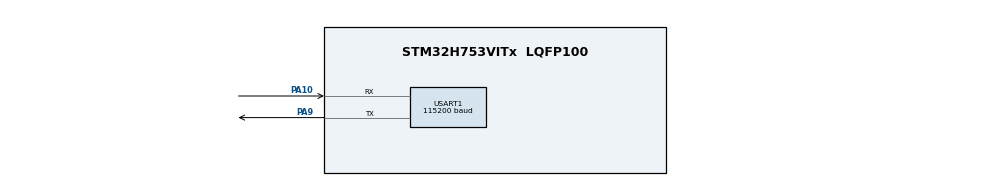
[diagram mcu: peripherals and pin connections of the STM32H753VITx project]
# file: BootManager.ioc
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CORTEX_M7.default_mode_Activation=1
CRC.InputDataFormat=CRC_INPUTDATA_FORMAT_WORDS
Mcu.Family=STM32H7
Mcu.Name=STM32H753VITx
Mcu.Package=LQFP100
NVIC.PriorityGroup=NVIC_PRIORITYGROUP_4
NVIC.USART1_IRQn=true\:0\:0\:false\:false\:true\:true\:true\:true
PA10.Mode=Asynchronous
PA10.Signal=USART1_RX
PA9.Mode=Asynchronous
PA9.Signal=USART1_TX
ProjectManager.HeapSize=0x200
ProjectManager.StackSize=0x400
ProjectManager.TargetToolchain=STM32CubeIDE
RCC.ADCFreq_Value=129000000
RCC.APB1Freq_Value=80000000
RCC.APB2Freq_Value=40000000
RCC.APB3Freq_Value=80000000
RCC.APB4Freq_Value=80000000
RCC.CortexFreq_Value=80000000
RCC.D2PPRE2=RCC_APB2_DIV2
RCC.DIVM1=4
RCC.DIVN1=10
RCC.HCLKFreq_Value=80000000
RCC.PLLFRACN=0
RCC.SYSCLKFreq_VALUE=80000000
RCC.SYSCLKSource=RCC_SYSCLKSOURCE_PLLCLK
RCC.USBFreq_Value=80000000
USART1.BaudRate=115200
USART1.Parity=PARITY_EVEN
USART1.VirtualMode-Asynchronous=VM_ASYNC
USART1.WordLength=WORDLENGTH_9B
VP_CRC_VS_CRC.Mode=CRC_Activate
VP_MEMORYMAP_VS_MEMORYMAP.Mode=CurAppReg
VP_RTC_VS_RTC_Activate.Mode=RTC_Enabled
board=custom

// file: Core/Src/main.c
/* USER CODE BEGIN Header */
/**
  ******************************************************************************
  * @file           : main.c
  * @author 		: Anthony Santos
  * @version 	  	: 1.0.0
  * @brief          : Boot manager entry point and application validation logic
  ******************************************************************************
  * @attention
  *
  * Copyright (c) 2025 STMicroelectronics.
  * All rights reserved.
  *
  * This software is licensed under terms that can be found in the LICENSE file
  * in the root directory of this software component.
  * If no LICENSE file comes with this software, it is provided AS-IS.
  *
  ******************************************************************************
  */
/* USER CODE END Header */
#include "main.h"

/* USER CODE BEGIN Includes */
#include <stdio.h>
#include <stdbool.h>
#include <string.h>
/* USER CODE END Includes */

/* USER CODE BEGIN PTD */
typedef  void (*pFunction)(void);
/* USER CODE END PTD */

/* USER CODE BEGIN PD */
#define BOOTLOADER_FLAG_ADDR ((uint32_t*)0x2001FFF0)
#define BOOTLOADER_FLAG_VALUE 0xDEADBEEF
#define BOOTLOADER_ADDRESS 0x1FF09800
#define APP_ADDRESS  0x08020000
#define APP_CRC_ADDRESS 0x08040000
#define APP_CRC_LENGTH (APP_CRC_ADDRESS - APP_ADDRESS)
/* USER CODE END PD */

CRC_HandleTypeDef hcrc;

RTC_HandleTypeDef hrtc;

UART_HandleTypeDef huart1;

/* USER CODE BEGIN PV */
uint32_t *bootloader_flag;
pFunction JumpToBootloader;
pFunction JumpToApp;
uint32_t JumpAddressBoot;
uint32_t JumpAddressApp;
extern uint32_t _app_image_end;
/* USER CODE END PV */

void SystemClock_Config(void);
static void MPU_Config(void);
static void MX_GPIO_Init(void);
static void MX_RTC_Init(void);
static void MX_USART1_UART_Init(void);
static void MX_CRC_Init(void);

/* USER CODE BEGIN 0 */

/* USER CODE BEGIN 0 */

/**
 * @brief  A manual boot window upon this bootmanagers startup that waits for command 2B.
 * 		   Upon the command being triggered we will jump to bootloader.
 * 		   If no command is sent over UART, code continues as normal.
 */
static void WaitForManualBootWindow(void)
{
    // Flush any stale RX data so we only react to *new* traffic
    __HAL_UART_FLUSH_DRREGISTER(&huart1);
    __HAL_UART_CLEAR_OREFLAG(&huart1);
    __HAL_UART_CLEAR_NEFLAG(&huart1);
    __HAL_UART_CLEAR_FEFLAG(&huart1);
    __HAL_UART_CLEAR_PEFLAG(&huart1);

    const char *msg = "BootMgr: 1s window open — send 0x2B to enter ST bootloader...\r\n";
    HAL_UART_Transmit(&huart1, (uint8_t*)msg, strlen(msg), HAL_MAX_DELAY);

    uint32_t start = HAL_GetTick();
    uint8_t byte = 0;

    while ((HAL_GetTick() - start) < 1000UL)   // ~1 second window
    {
        // Short, non-blocking-ish read (10 ms slices)
        if (HAL_UART_Receive(&huart1, &byte, 1, 10) == HAL_OK)
        {
            if (byte == 0x2B) // '+' == 0x2B
            {
                const char *trig = "BootMgr: Manual bootloader request detected. Jumping...\r\n";
                HAL_UART_Transmit(&huart1, (uint8_t*)trig, strlen(trig), HAL_MAX_DELAY);

                // Optional: clear any RAM flag so we don't loop back here later by accident
                // *BOOTLOADER_FLAG_ADDR = 0;

                JumpToSystemBootloader();
                // no return
            }
            // If you expect larger protocol frames later, you could keep consuming here;
            // for now, any non-0x2B byte is ignored and the window continues.
        }
        // else: timeout -> keep looping until 1s total has elapsed
    }
}
/* USER CODE END 0 */

/**
 * @brief  Jump to the STM32 System Bootloader (e.g. during corrupt state or UART-based flashing).
 *         Cleans up peripherals and disables interrupts before jumping to the
 *         system memory bootloader address.
 */
void JumpToSystemBootloader(void)
{
	uint32_t i=0;
	void (*SysMemBootJump)(void);

	__disable_irq();
	HAL_UART_DeInit(&huart1);
	HAL_RCC_DeInit();
	HAL_RTC_DeInit(&hrtc);
	HAL_CRC_DeInit(&hcrc);
	HAL_DeInit();
	__HAL_RCC_CRC_CLK_DISABLE();

	// Disable Systick
	SysTick->CTRL = 0;
	SysTick->LOAD = 0;
	SysTick->VAL = 0;

	// Reset clock config
	HAL_RCC_DeInit();

	// Clear NVIC interrupt enable and pending registers
	for (i=0;i<5;i++)
	{
		NVIC->ICER[i]=0xFFFFFFFF;
		NVIC->ICPR[i]=0xFFFFFFFF;
	}

	// Re-enable all interrupts
	__enable_irq();

	SysMemBootJump = (void (*)(void)) (*((uint32_t *) ((BOOTLOADER_ADDRESS + 4))));
	__set_MSP(*(uint32_t *) BOOTLOADER_ADDRESS);
	SysMemBootJump();
}

/**
 * @brief  Jump to user application code located at APP_ADDRESS.
 *         Verifies and sets the application's stack pointer and PC.
 */
void JumpToApplication(void)
{
	__disable_irq();

	// Optional but good practice
	HAL_UART_DeInit(&huart1);
	HAL_RCC_DeInit();
	HAL_RTC_DeInit(&hrtc);
	HAL_CRC_DeInit(&hcrc);
	HAL_DeInit();
	__HAL_RCC_CRC_CLK_DISABLE();

	// Kill SysTick
	SysTick->CTRL = 0;
	SysTick->LOAD = 0;
	SysTick->VAL  = 0;

	// Disable all NVIC IRQs
	for (int i = 0; i < 5; i++) {
		NVIC->ICER[i] = 0xFFFFFFFF;
		NVIC->ICPR[i] = 0xFFFFFFFF;
	}

	SCB->VTOR = APP_ADDRESS;

	// Set MSP and jump
	uint32_t app_stack = *(volatile uint32_t*)APP_ADDRESS;
	uint32_t app_reset = *(volatile uint32_t*)(APP_ADDRESS + 4);
	__set_MSP(app_stack);
	void (*app_entry)(void) = (void*)app_reset;

	app_entry();
	while(1);
}

/**
 * @brief  Validates application code by checking its initial stack pointer and reset vector.
 * @retval true if both SP and PC are in valid memory ranges and the PC has the Thumb bit set.
 */
bool IsApplicationValid(void)
{
    uint32_t appStack = *(__IO uint32_t*)APP_ADDRESS;
    uint32_t appResetHandler = *(__IO uint32_t*)(APP_ADDRESS + 4);

    // Reject if either value is erased / corrupt
   if (appStack == 0xFFFFFFFF || appResetHandler == 0xFFFFFFFF)
	   return false;

    bool stack_valid =
        ((appStack >= 0x24000000U && appStack <= 0x2407FFFFU) ||
         (appStack >= 0x20000000U && appStack <= 0x2001FFFFU) ||
         (appStack >= 0x30000000U && appStack <= 0x30047FFFU) ||
         (appStack >= 0x38000000U && appStack <= 0x3800FFFFU));
    bool reset_valid = (appResetHandler >= APP_ADDRESS &&
                        appResetHandler <= 0x080FFFFF &&
                        (appResetHandler & 0x1)); // Thumb bit set
    char msg[100];
        snprintf(msg, sizeof(msg), "Validating App:\r\n  SP Valid: %s\r\n  PC Valid: %s\r\n",
                 stack_valid ? "YES" : "NO",
                 reset_valid ? "YES" : "NO");
        HAL_UART_Transmit(&huart1, (uint8_t*)msg, strlen(msg), HAL_MAX_DELAY);
    return stack_valid && reset_valid;
}

/**
 * @brief  Validates the application using CRC32.
 *         Computes CRC over app region and compares it with stored value at APP_CRC_ADDRESS.
 * @retval true if CRC matches
 */
bool IsApplicationValidCRC(void)
{
    __HAL_RCC_CRC_CLK_ENABLE();
    HAL_CRC_DeInit(&hcrc);
    HAL_CRC_Init(&hcrc);
    __HAL_CRC_DR_RESET(&hcrc);

    uint8_t* app_bytes = (uint8_t*)APP_ADDRESS;
    uint32_t length_bytes = (APP_CRC_ADDRESS - APP_ADDRESS);

    uint32_t crc_value = 0xFFFFFFFF;
    for (uint32_t i = 0; i < length_bytes; ++i)
    {
        uint32_t i_data = app_bytes[i];
        crc_value = HAL_CRC_Accumulate(&hcrc, &i_data, 1);
    }

    uint32_t stored_crc = *(uint32_t*)APP_CRC_ADDRESS;

    char msg[128];
    snprintf(msg, sizeof(msg),
             "Validating App CRC (bytewise):\r\n  Calculated: 0x%08lX\r\n  Stored:     0x%08lX\r\n  Match:      %s\r\n",
             crc_value, stored_crc, (crc_value == stored_crc) ? "YES" : "NO");
    HAL_UART_Transmit(&huart1, (uint8_t*)msg, strlen(msg), HAL_MAX_DELAY);

    return crc_value == stored_crc;
}

/* USER CODE END 0 */

int main(void)
{

  /* MPU Configuration--------------------------------------------------------*/
  MPU_Config();

  /* MCU Configuration--------------------------------------------------------*/

  /* Reset of all peripherals, Initializes the Flash interface and the Systick. */
  HAL_Init();

  /* Configure the system clock */
  SystemClock_Config();

  /* Initialize all configured peripherals */
  MX_GPIO_Init();
  MX_RTC_Init();
  MX_USART1_UART_Init();
  MX_CRC_Init();
  /* USER CODE BEGIN 2 */
  WaitForManualBootWindow();

  if (*BOOTLOADER_FLAG_ADDR == BOOTLOADER_FLAG_VALUE) {
      *BOOTLOADER_FLAG_ADDR = 0;  // Clear flag
      const char *msg = "BootMgr: Bootloader flag triggered. Jumping to ST bootloader...\r\n";
      HAL_UART_Transmit(&huart1, (uint8_t*)msg, strlen(msg), HAL_MAX_DELAY);
//      HAL_Delay(1000);
      JumpToSystemBootloader();
  }

  if (IsApplicationValid() && IsApplicationValidCRC()) {
	  const char *msg = "BootMgr: Application valid. Jumping to application...\r\n";
	  HAL_UART_Transmit(&huart1, (uint8_t*)msg, strlen(msg), HAL_MAX_DELAY);
//      HAL_Delay(1000);
      JumpToApplication();
  } else {
	  const char *msg = "BootMgr: Application invalid. Jumping to ST bootloader...\r\n";
	  HAL_UART_Transmit(&huart1, (uint8_t*)msg, strlen(msg), HAL_MAX_DELAY);
//      HAL_Delay(1000);
      JumpToSystemBootloader();
  }
  /* USER CODE END 2 */

  /* Infinite loop */
  while (1)
  {

  }
}

void SystemClock_Config(void)
{
  RCC_OscInitTypeDef RCC_OscInitStruct = {0};
  RCC_ClkInitTypeDef RCC_ClkInitStruct = {0};

  /** Supply configuration update enable
  */
  HAL_PWREx_ConfigSupply(PWR_LDO_SUPPLY);

  /** Configure the main internal regulator output voltage
  */
  __HAL_PWR_VOLTAGESCALING_CONFIG(PWR_REGULATOR_VOLTAGE_SCALE3);

  while(!__HAL_PWR_GET_FLAG(PWR_FLAG_VOSRDY)) {}

  /** Initializes the RCC Oscillators according to the specified parameters
  * in the RCC_OscInitTypeDef structure.
  */
  RCC_OscInitStruct.OscillatorType = RCC_OSCILLATORTYPE_HSI|RCC_OSCILLATORTYPE_LSI;
  RCC_OscInitStruct.HSIState = RCC_HSI_DIV1;
  RCC_OscInitStruct.HSICalibrationValue = RCC_HSICALIBRATION_DEFAULT;
  RCC_OscInitStruct.LSIState = RCC_LSI_ON;
  RCC_OscInitStruct.PLL.PLLState = RCC_PLL_ON;
  RCC_OscInitStruct.PLL.PLLSource = RCC_PLLSOURCE_HSI;
  RCC_OscInitStruct.PLL.PLLM = 4;
  RCC_OscInitStruct.PLL.PLLN = 10;
  RCC_OscInitStruct.PLL.PLLP = 2;
  RCC_OscInitStruct.PLL.PLLQ = 2;
  RCC_OscInitStruct.PLL.PLLR = 2;
  RCC_OscInitStruct.PLL.PLLRGE = RCC_PLL1VCIRANGE_3;
  RCC_OscInitStruct.PLL.PLLVCOSEL = RCC_PLL1VCOMEDIUM;
  RCC_OscInitStruct.PLL.PLLFRACN = 0;
  if (HAL_RCC_OscConfig(&RCC_OscInitStruct) != HAL_OK)
  {
    Error_Handler();
  }

  /** Initializes the CPU, AHB and APB buses clocks
  */
  RCC_ClkInitStruct.ClockType = RCC_CLOCKTYPE_HCLK|RCC_CLOCKTYPE_SYSCLK
                              |RCC_CLOCKTYPE_PCLK1|RCC_CLOCKTYPE_PCLK2
                              |RCC_CLOCKTYPE_D3PCLK1|RCC_CLOCKTYPE_D1PCLK1;
  RCC_ClkInitStruct.SYSCLKSource = RCC_SYSCLKSOURCE_PLLCLK;
  RCC_ClkInitStruct.SYSCLKDivider = RCC_SYSCLK_DIV1;
  RCC_ClkInitStruct.AHBCLKDivider = RCC_HCLK_DIV1;
  RCC_ClkInitStruct.APB3CLKDivider = RCC_APB3_DIV1;
  RCC_ClkInitStruct.APB1CLKDivider = RCC_APB1_DIV1;
  RCC_ClkInitStruct.APB2CLKDivider = RCC_APB2_DIV2;
  RCC_ClkInitStruct.APB4CLKDivider = RCC_APB4_DIV1;

  if (HAL_RCC_ClockConfig(&RCC_ClkInitStruct, FLASH_LATENCY_1) != HAL_OK)
  {
    Error_Handler();
  }
}

static void MX_CRC_Init(void)
{

  hcrc.Instance = CRC;
  hcrc.Init.DefaultPolynomialUse = DEFAULT_POLYNOMIAL_ENABLE;
  hcrc.Init.DefaultInitValueUse = DEFAULT_INIT_VALUE_ENABLE;
  hcrc.Init.InputDataInversionMode = CRC_INPUTDATA_INVERSION_NONE;
  hcrc.Init.OutputDataInversionMode = CRC_OUTPUTDATA_INVERSION_DISABLE;
  hcrc.InputDataFormat = CRC_INPUTDATA_FORMAT_WORDS;
  if (HAL_CRC_Init(&hcrc) != HAL_OK)
  {
    Error_Handler();
  }

}

static void MX_RTC_Init(void)
{

  /** Initialize RTC Only
  */
  hrtc.Instance = RTC;
  hrtc.Init.HourFormat = RTC_HOURFORMAT_24;
  hrtc.Init.AsynchPrediv = 127;
  hrtc.Init.SynchPrediv = 255;
  hrtc.Init.OutPut = RTC_OUTPUT_DISABLE;
  hrtc.Init.OutPutPolarity = RTC_OUTPUT_POLARITY_HIGH;
  hrtc.Init.OutPutType = RTC_OUTPUT_TYPE_OPENDRAIN;
  hrtc.Init.OutPutRemap = RTC_OUTPUT_REMAP_NONE;
  if (HAL_RTC_Init(&hrtc) != HAL_OK)
  {
    Error_Handler();
  }

}

static void MX_USART1_UART_Init(void)
{

  huart1.Instance = USART1;
  huart1.Init.BaudRate = 115200;
  huart1.Init.WordLength = UART_WORDLENGTH_9B;
  huart1.Init.StopBits = UART_STOPBITS_1;
  huart1.Init.Parity = UART_PARITY_EVEN;
  huart1.Init.Mode = UART_MODE_TX_RX;
  huart1.Init.HwFlowCtl = UART_HWCONTROL_NONE;
  huart1.Init.OverSampling = UART_OVERSAMPLING_16;
  huart1.Init.OneBitSampling = UART_ONE_BIT_SAMPLE_DISABLE;
  huart1.Init.ClockPrescaler = UART_PRESCALER_DIV1;
  huart1.AdvancedInit.AdvFeatureInit = UART_ADVFEATURE_NO_INIT;
  if (HAL_UART_Init(&huart1) != HAL_OK)
  {
    Error_Handler();
  }
  if (HAL_UARTEx_SetTxFifoThreshold(&huart1, UART_TXFIFO_THRESHOLD_1_8) != HAL_OK)
  {
    Error_Handler();
  }
  if (HAL_UARTEx_SetRxFifoThreshold(&huart1, UART_RXFIFO_THRESHOLD_1_8) != HAL_OK)
  {
    Error_Handler();
  }
  if (HAL_UARTEx_DisableFifoMode(&huart1) != HAL_OK)
  {
    Error_Handler();
  }

}

static void MX_GPIO_Init(void)
{

  /* GPIO Ports Clock Enable */
  __HAL_RCC_GPIOA_CLK_ENABLE();

}

 /* MPU Configuration */

void MPU_Config(void)
{
  MPU_Region_InitTypeDef MPU_InitStruct = {0};

  /* Disables the MPU */
  HAL_MPU_Disable();

  /** Initializes and configures the Region and the memory to be protected
  */
  MPU_InitStruct.Enable = MPU_REGION_ENABLE;
  MPU_InitStruct.Number = MPU_REGION_NUMBER0;
  MPU_InitStruct.BaseAddress = 0x0;
  MPU_InitStruct.Size = MPU_REGION_SIZE_4GB;
  MPU_InitStruct.SubRegionDisable = 0x87;
  MPU_InitStruct.TypeExtField = MPU_TEX_LEVEL0;
  MPU_InitStruct.AccessPermission = MPU_REGION_NO_ACCESS;
  MPU_InitStruct.DisableExec = MPU_INSTRUCTION_ACCESS_DISABLE;
  MPU_InitStruct.IsShareable = MPU_ACCESS_SHAREABLE;
  MPU_InitStruct.IsCacheable = MPU_ACCESS_NOT_CACHEABLE;
  MPU_InitStruct.IsBufferable = MPU_ACCESS_NOT_BUFFERABLE;

  HAL_MPU_ConfigRegion(&MPU_InitStruct);
  /* Enables the MPU */
  HAL_MPU_Enable(MPU_PRIVILEGED_DEFAULT);

}

void Error_Handler(void)
{
  __disable_irq();
  while (1)
  {
  }
}
